[part 1 of 2: package /Nexteer/NvMProxy_swc/ComponentTypes]
AUTOSAR XML (schema 4-0-3)
package /Nexteer/NvMProxy_swc/ComponentTypes
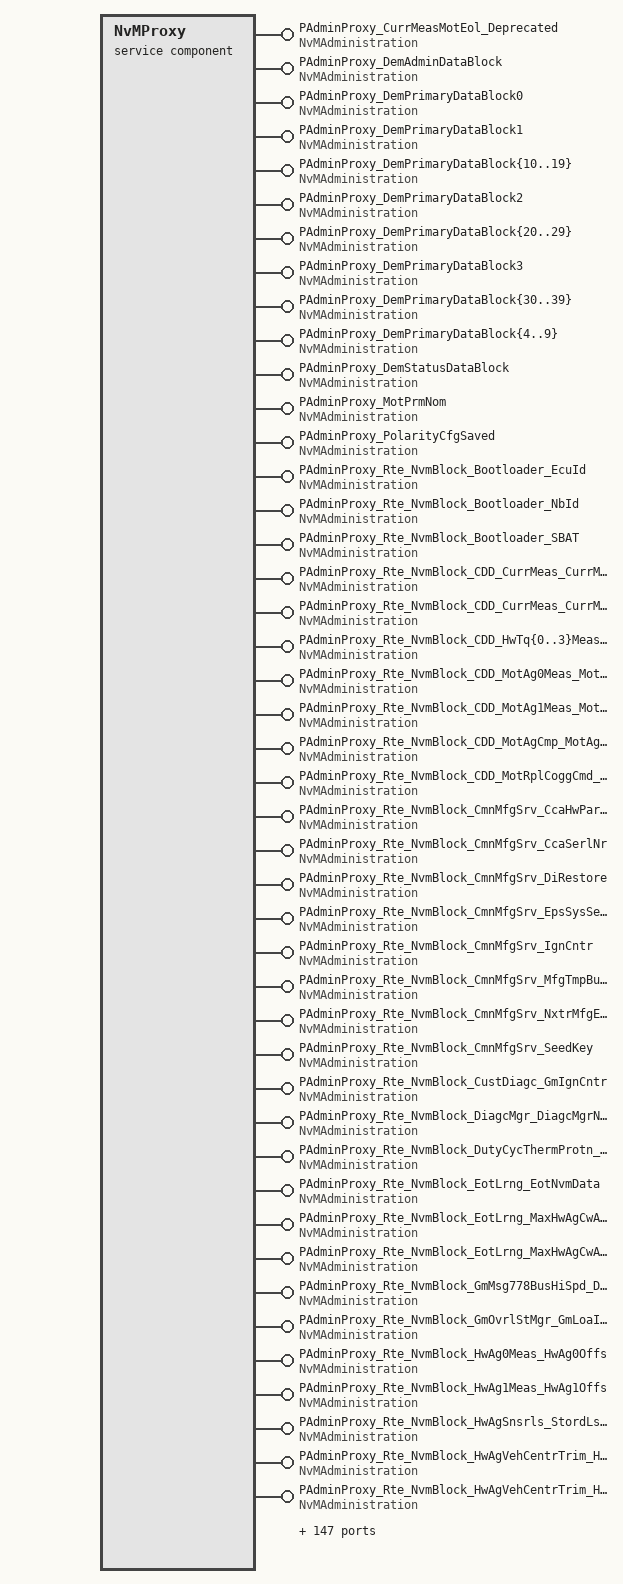
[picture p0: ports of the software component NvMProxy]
  service sw component type NvMProxy
    232 x provide port:
      PAdminProxy_CurrMeasMotEol_Deprecated: server-com-spec{operation=SetBlockProtection, queue-length=1}, provided-interface=NvMAdministration
      PAdminProxy_DemAdminDataBlock: server-com-spec{operation=SetBlockProtection, queue-length=1}, provided-interface=NvMAdministration
      PAdminProxy_DemPrimaryDataBlock0: server-com-spec{operation=SetBlockProtection, queue-length=1}, provided-interface=NvMAdministration
      PAdminProxy_DemPrimaryDataBlock1: server-com-spec{operation=SetBlockProtection, queue-length=1}, provided-interface=NvMAdministration
      PAdminProxy_DemPrimaryDataBlock{10..19}: server-com-spec{operation=SetBlockProtection, queue-length=1}, provided-interface=NvMAdministration
      PAdminProxy_DemPrimaryDataBlock2: server-com-spec{operation=SetBlockProtection, queue-length=1}, provided-interface=NvMAdministration
      PAdminProxy_DemPrimaryDataBlock{20..29}: server-com-spec{operation=SetBlockProtection, queue-length=1}, provided-interface=NvMAdministration
      PAdminProxy_DemPrimaryDataBlock3: server-com-spec{operation=SetBlockProtection, queue-length=1}, provided-interface=NvMAdministration
      PAdminProxy_DemPrimaryDataBlock{30..39}: server-com-spec{operation=SetBlockProtection, queue-length=1}, provided-interface=NvMAdministration
      PAdminProxy_DemPrimaryDataBlock{4..9}: server-com-spec{operation=SetBlockProtection, queue-length=1}, provided-interface=NvMAdministration
      PAdminProxy_DemStatusDataBlock: server-com-spec{operation=SetBlockProtection, queue-length=1}, provided-interface=NvMAdministration
      PAdminProxy_MotPrmNom: server-com-spec{operation=SetBlockProtection, queue-length=1}, provided-interface=NvMAdministration
      PAdminProxy_PolarityCfgSaved: server-com-spec{operation=SetBlockProtection, queue-length=1}, provided-interface=NvMAdministration
      PAdminProxy_Rte_NvmBlock_Bootloader_EcuId: server-com-spec{operation=SetBlockProtection, queue-length=1}, provided-interface=NvMAdministration
      PAdminProxy_Rte_NvmBlock_Bootloader_NbId: server-com-spec{operation=SetBlockProtection, queue-length=1}, provided-interface=NvMAdministration
      PAdminProxy_Rte_NvmBlock_Bootloader_SBAT: server-com-spec{operation=SetBlockProtection, queue-length=1}, provided-interface=NvMAdministration
      PAdminProxy_Rte_NvmBlock_CDD_CurrMeas_CurrMeasEolGainCalSet: server-com-spec{operation=SetBlockProtection, queue-length=1}, provided-interface=NvMAdministration
      PAdminProxy_Rte_NvmBlock_CDD_CurrMeas_CurrMeasEolOffsCalSet: server-com-spec{operation=SetBlockProtection, queue-length=1}, provided-interface=NvMAdministration
      PAdminProxy_Rte_NvmBlock_CDD_HwTq{0..3}Meas_HwTq{0..3}Offs: server-com-spec{operation=SetBlockProtection, queue-length=1}, provided-interface=NvMAdministration
      PAdminProxy_Rte_NvmBlock_CDD_MotAg0Meas_MotAg0CoeffTbl: server-com-spec{operation=SetBlockProtection, queue-length=1}, provided-interface=NvMAdministration
      PAdminProxy_Rte_NvmBlock_CDD_MotAg1Meas_MotAg1CoeffTbl: server-com-spec{operation=SetBlockProtection, queue-length=1}, provided-interface=NvMAdministration
      PAdminProxy_Rte_NvmBlock_CDD_MotAgCmp_MotAgCmpMotAgBackEmf: server-com-spec{operation=SetBlockProtection, queue-length=1}, provided-interface=NvMAdministration
      PAdminProxy_Rte_NvmBlock_CDD_MotRplCoggCmd_MotCoggCmdY: server-com-spec{operation=SetBlockProtection, queue-length=1}, provided-interface=NvMAdministration
      PAdminProxy_Rte_NvmBlock_CmnMfgSrv_CcaHwPartNr: server-com-spec{operation=SetBlockProtection, queue-length=1}, provided-interface=NvMAdministration
      PAdminProxy_Rte_NvmBlock_CmnMfgSrv_CcaSerlNr: server-com-spec{operation=SetBlockProtection, queue-length=1}, provided-interface=NvMAdministration
      PAdminProxy_Rte_NvmBlock_CmnMfgSrv_DiRestore: server-com-spec{operation=SetBlockProtection, queue-length=1}, provided-interface=NvMAdministration
      PAdminProxy_Rte_NvmBlock_CmnMfgSrv_EpsSysSerlNr: server-com-spec{operation=SetBlockProtection, queue-length=1}, provided-interface=NvMAdministration
      PAdminProxy_Rte_NvmBlock_CmnMfgSrv_IgnCntr: server-com-spec{operation=SetBlockProtection, queue-length=1}, provided-interface=NvMAdministration
      PAdminProxy_Rte_NvmBlock_CmnMfgSrv_MfgTmpBuf{0..4}: server-com-spec{operation=SetBlockProtection, queue-length=1}, provided-interface=NvMAdministration
      PAdminProxy_Rte_NvmBlock_CmnMfgSrv_NxtrMfgEnaCntr: server-com-spec{operation=SetBlockProtection, queue-length=1}, provided-interface=NvMAdministration
      PAdminProxy_Rte_NvmBlock_CmnMfgSrv_SeedKey: server-com-spec{operation=SetBlockProtection, queue-length=1}, provided-interface=NvMAdministration
      PAdminProxy_Rte_NvmBlock_CustDiagc_GmIgnCntr: server-com-spec{operation=SetBlockProtection, queue-length=1}, provided-interface=NvMAdministration
      PAdminProxy_Rte_NvmBlock_DiagcMgr_DiagcMgrNtcFltAry: server-com-spec{operation=SetBlockProtection, queue-length=1}, provided-interface=NvMAdministration
      PAdminProxy_Rte_NvmBlock_DutyCycThermProtn_FilStVal: server-com-spec{operation=SetBlockProtection, queue-length=1}, provided-interface=NvMAdministration
      PAdminProxy_Rte_NvmBlock_EotLrng_EotNvmData: server-com-spec{operation=SetBlockProtection, queue-length=1}, provided-interface=NvMAdministration
      PAdminProxy_Rte_NvmBlock_EotLrng_MaxHwAgCwAndCcw: server-com-spec{operation=SetBlockProtection, queue-length=1}, provided-interface=NvMAdministration
      PAdminProxy_Rte_NvmBlock_EotLrng_MaxHwAgCwAndCcw_Deprecated: server-com-spec{operation=SetBlockProtection, queue-length=1}, provided-interface=NvMAdministration
      PAdminProxy_Rte_NvmBlock_GmMsg778BusHiSpd_DtcTrigStsAry: server-com-spec{operation=SetBlockProtection, queue-length=1}, provided-interface=NvMAdministration
      PAdminProxy_Rte_NvmBlock_GmOvrlStMgr_GmLoaIgnCntr: server-com-spec{operation=SetBlockProtection, queue-length=1}, provided-interface=NvMAdministration
      PAdminProxy_Rte_NvmBlock_HwAg0Meas_HwAg0Offs: server-com-spec{operation=SetBlockProtection, queue-length=1}, provided-interface=NvMAdministration
      PAdminProxy_Rte_NvmBlock_HwAg1Meas_HwAg1Offs: server-com-spec{operation=SetBlockProtection, queue-length=1}, provided-interface=NvMAdministration
      PAdminProxy_Rte_NvmBlock_HwAgSnsrls_StordLstPrm: server-com-spec{operation=SetBlockProtection, queue-length=1}, provided-interface=NvMAdministration
      PAdminProxy_Rte_NvmBlock_HwAgVehCentrTrim_HwAgTrimData: server-com-spec{operation=SetBlockProtection, queue-length=1}, provided-interface=NvMAdministration
      PAdminProxy_Rte_NvmBlock_HwAgVehCentrTrim_HwAgTrimVal_Deprecated: server-com-spec{operation=SetBlockProtection, queue-length=1}, provided-interface=NvMAdministration
      PAdminProxy_Rte_NvmBlock_HwTqCorrln_HwTqChACmnModCmpLpFilSt: server-com-spec{operation=SetBlockProtection, queue-length=1}, provided-interface=NvMAdministration
      PAdminProxy_Rte_NvmBlock_HwTqCorrln_HwTqChBCmnModCmpLpFilSt: server-com-spec{operation=SetBlockProtection, queue-length=1}, provided-interface=NvMAdministration
      PAdminProxy_Rte_NvmBlock_MotAg2Meas_MotAg2EolPrm: server-com-spec{operation=SetBlockProtection, queue-length=1}, provided-interface=NvMAdministration
      PAdminProxy_Rte_NvmBlock_MotRplCoggCfg_MotRplCoggPrm: server-com-spec{operation=SetBlockProtection, queue-length=1}, provided-interface=NvMAdministration
      PAdminProxy_Rte_NvmBlock_MotTqCmdSca_MotTqScaFac: server-com-spec{operation=SetBlockProtection, queue-length=1}, provided-interface=NvMAdministration
      PAdminProxy_Rte_NvmBlock_NvMProxy_ShtdwnClsChk: server-com-spec{operation=SetBlockProtection, queue-length=1}, provided-interface=NvMAdministration
      PAdminProxy_Rte_NvmBlock_PartNr_PartNrBasMdlPartNr: server-com-spec{operation=SetBlockProtection, queue-length=1}, provided-interface=NvMAdministration
      PAdminProxy_Rte_NvmBlock_PartNr_PartNrCalProgdSts: server-com-spec{operation=SetBlockProtection, queue-length=1}, provided-interface=NvMAdministration
      PAdminProxy_Rte_NvmBlock_PartNr_PartNrCcaMfgTrakg: server-com-spec{operation=SetBlockProtection, queue-length=1}, provided-interface=NvMAdministration
      PAdminProxy_Rte_NvmBlock_PartNr_PartNrCtrlPidSeedKey: server-com-spec{operation=SetBlockProtection, queue-length=1}, provided-interface=NvMAdministration
      PAdminProxy_Rte_NvmBlock_PartNr_PartNrCustMfgEnaCntr: server-com-spec{operation=SetBlockProtection, queue-length=1}, provided-interface=NvMAdministration
      PAdminProxy_Rte_NvmBlock_PartNr_PartNrDataUniversalNrSysId: server-com-spec{operation=SetBlockProtection, queue-length=1}, provided-interface=NvMAdministration
      PAdminProxy_Rte_NvmBlock_PartNr_PartNrEndMdlPartNr: server-com-spec{operation=SetBlockProtection, queue-length=1}, provided-interface=NvMAdministration
      PAdminProxy_Rte_NvmBlock_PartNr_PartNrNxtrMfgTrakg: server-com-spec{operation=SetBlockProtection, queue-length=1}, provided-interface=NvMAdministration
      PAdminProxy_Rte_NvmBlock_PartNr_PartNrProgmDate: server-com-spec{operation=SetBlockProtection, queue-length=1}, provided-interface=NvMAdministration
      PAdminProxy_Rte_NvmBlock_PartNr_PartNrProgmSessionSeedKey: server-com-spec{operation=SetBlockProtection, queue-length=1}, provided-interface=NvMAdministration
      PAdminProxy_Rte_NvmBlock_PartNr_PartNrRepairShopCod: server-com-spec{operation=SetBlockProtection, queue-length=1}, provided-interface=NvMAdministration
      PAdminProxy_Rte_NvmBlock_PartNr_PartNrSysCodVersNr: server-com-spec{operation=SetBlockProtection, queue-length=1}, provided-interface=NvMAdministration
      PAdminProxy_Rte_NvmBlock_PartNr_PartNrSysName: server-com-spec{operation=SetBlockProtection, queue-length=1}, provided-interface=NvMAdministration
      PAdminProxy_Rte_NvmBlock_PartNr_PartNrVinData: server-com-spec{operation=SetBlockProtection, queue-length=1}, provided-interface=NvMAdministration
      PAdminProxy_Rte_NvmBlock_PullCmpActv_PullCmpLongTerm: server-com-spec{operation=SetBlockProtection, queue-length=1}, provided-interface=NvMAdministration
      PAdminProxy_Rte_NvmBlock_SnsrOffsLrng_SnsrOffsLrnd: server-com-spec{operation=SetBlockProtection, queue-length=1}, provided-interface=NvMAdministration
      PAdminProxy_Rte_NvmBlock_StHlthSigStc_SigStcHistDataAry: server-com-spec{operation=SetBlockProtection, queue-length=1}, provided-interface=NvMAdministration
      PAdminProxy_Rte_NvmBlock_SysFricLrng_FricLrngData: server-com-spec{operation=SetBlockProtection, queue-length=1}, provided-interface=NvMAdministration
      PAdminProxy_Rte_NvmBlock_SysFricLrng_FricNonLrngData: server-com-spec{operation=SetBlockProtection, queue-length=1}, provided-interface=NvMAdministration
      PAdminProxy_Rte_NvmBlock_WhlImbRejctn_ActvCmpBand{1..3}_Deprecated: server-com-spec{operation=SetBlockProtection, queue-length=1}, provided-interface=NvMAdministration
      PAdminProxy_Rte_NvmBlock_WhlImbRejctn_CmpPeakData: server-com-spec{operation=SetBlockProtection, queue-length=1}, provided-interface=NvMAdministration
      PAdminProxy_Rte_NvmBlock_WhlImbRejctn_LePeakPrev_Deprecated: server-com-spec{operation=SetBlockProtection, queue-length=1}, provided-interface=NvMAdministration
      PAdminProxy_Rte_NvmBlock_WhlImbRejctn_MaxCompPerc_Deprecated: server-com-spec{operation=SetBlockProtection, queue-length=1}, provided-interface=NvMAdministration
      PAdminProxy_Rte_NvmBlock_WhlImbRejctn_RiPeakPrev_Deprecated: server-com-spec{operation=SetBlockProtection, queue-length=1}, provided-interface=NvMAdministration
      PAdminProxy_SnpshtDataAry: server-com-spec{operation=SetBlockProtection, queue-length=1}, provided-interface=NvMAdministration
      PSProxy_CurrMeasMotEol_Deprecated: provided-interface=NvMService_AC3_SRBS
        provided-com-specs:
          operation=EraseBlock, queue-length=1
          operation=GetErrorStatus, queue-length=1
          operation=InvalidateNvBlock, queue-length=1
          operation=ReadBlock, queue-length=1
          operation=SetRamBlockStatus, queue-length=1
          operation=WriteBlock, queue-length=1
      PSProxy_DemAdminDataBlock: provided-interface=NvMService_AC3_SRBS
        provided-com-specs:
          operation=EraseBlock, queue-length=1
          operation=GetErrorStatus, queue-length=1
          operation=InvalidateNvBlock, queue-length=1
          operation=ReadBlock, queue-length=1
          operation=SetRamBlockStatus, queue-length=1
          operation=WriteBlock, queue-length=1
      PSProxy_DemPrimaryDataBlock0: provided-interface=NvMService_AC3_SRBS_Defs
        provided-com-specs:
          operation=EraseBlock, queue-length=1
          operation=GetErrorStatus, queue-length=1
          operation=InvalidateNvBlock, queue-length=1
          operation=ReadBlock, queue-length=1
          operation=RestoreBlockDefaults, queue-length=1
          operation=SetRamBlockStatus, queue-length=1
          operation=WriteBlock, queue-length=1
      PSProxy_DemPrimaryDataBlock1: provided-interface=NvMService_AC3_SRBS_Defs
        provided-com-specs:
          operation=EraseBlock, queue-length=1
          operation=GetErrorStatus, queue-length=1
          operation=InvalidateNvBlock, queue-length=1
          operation=ReadBlock, queue-length=1
          operation=RestoreBlockDefaults, queue-length=1
          operation=SetRamBlockStatus, queue-length=1
          operation=WriteBlock, queue-length=1
      PSProxy_DemPrimaryDataBlock10: provided-interface=NvMService_AC3_SRBS_Defs
        provided-com-specs:
          operation=EraseBlock, queue-length=1
          operation=GetErrorStatus, queue-length=1
          operation=InvalidateNvBlock, queue-length=1
          operation=ReadBlock, queue-length=1
          operation=RestoreBlockDefaults, queue-length=1
          operation=SetRamBlockStatus, queue-length=1
          operation=WriteBlock, queue-length=1
      PSProxy_DemPrimaryDataBlock11: provided-interface=NvMService_AC3_SRBS_Defs
        provided-com-specs:
          operation=EraseBlock, queue-length=1
          operation=GetErrorStatus, queue-length=1
          operation=InvalidateNvBlock, queue-length=1
          operation=ReadBlock, queue-length=1
          operation=RestoreBlockDefaults, queue-length=1
          operation=SetRamBlockStatus, queue-length=1
          operation=WriteBlock, queue-length=1
      PSProxy_DemPrimaryDataBlock12: provided-interface=NvMService_AC3_SRBS_Defs
        provided-com-specs:
          operation=EraseBlock, queue-length=1
          operation=GetErrorStatus, queue-length=1
          operation=InvalidateNvBlock, queue-length=1
          operation=ReadBlock, queue-length=1
          operation=RestoreBlockDefaults, queue-length=1
          operation=SetRamBlockStatus, queue-length=1
          operation=WriteBlock, queue-length=1
      PSProxy_DemPrimaryDataBlock13: provided-interface=NvMService_AC3_SRBS_Defs
        provided-com-specs:
          operation=EraseBlock, queue-length=1
          operation=GetErrorStatus, queue-length=1
          operation=InvalidateNvBlock, queue-length=1
          operation=ReadBlock, queue-length=1
          operation=RestoreBlockDefaults, queue-length=1
          operation=SetRamBlockStatus, queue-length=1
          operation=WriteBlock, queue-length=1
      PSProxy_DemPrimaryDataBlock14: provided-interface=NvMService_AC3_SRBS_Defs
        provided-com-specs:
          operation=EraseBlock, queue-length=1
          operation=GetErrorStatus, queue-length=1
          operation=InvalidateNvBlock, queue-length=1
          operation=ReadBlock, queue-length=1
          operation=RestoreBlockDefaults, queue-length=1
          operation=SetRamBlockStatus, queue-length=1
          operation=WriteBlock, queue-length=1
      PSProxy_DemPrimaryDataBlock15: provided-interface=NvMService_AC3_SRBS_Defs
        provided-com-specs:
          operation=EraseBlock, queue-length=1
          operation=GetErrorStatus, queue-length=1
          operation=InvalidateNvBlock, queue-length=1
          operation=ReadBlock, queue-length=1
          operation=RestoreBlockDefaults, queue-length=1
          operation=SetRamBlockStatus, queue-length=1
          operation=WriteBlock, queue-length=1
      PSProxy_DemPrimaryDataBlock16: provided-interface=NvMService_AC3_SRBS_Defs
        provided-com-specs:
          operation=EraseBlock, queue-length=1
          operation=GetErrorStatus, queue-length=1
          operation=InvalidateNvBlock, queue-length=1
          operation=ReadBlock, queue-length=1
          operation=RestoreBlockDefaults, queue-length=1
          operation=SetRamBlockStatus, queue-length=1
          operation=WriteBlock, queue-length=1
      PSProxy_DemPrimaryDataBlock17: provided-interface=NvMService_AC3_SRBS_Defs
        provided-com-specs:
          operation=EraseBlock, queue-length=1
          operation=GetErrorStatus, queue-length=1
          operation=InvalidateNvBlock, queue-length=1
          operation=ReadBlock, queue-length=1
          operation=RestoreBlockDefaults, queue-length=1
          operation=SetRamBlockStatus, queue-length=1
          operation=WriteBlock, queue-length=1
      PSProxy_DemPrimaryDataBlock18: provided-interface=NvMService_AC3_SRBS_Defs
        provided-com-specs:
          operation=EraseBlock, queue-length=1
          operation=GetErrorStatus, queue-length=1
          operation=InvalidateNvBlock, queue-length=1
          operation=ReadBlock, queue-length=1
          operation=RestoreBlockDefaults, queue-length=1
          operation=SetRamBlockStatus, queue-length=1
          operation=WriteBlock, queue-length=1
      PSProxy_DemPrimaryDataBlock19: provided-interface=NvMService_AC3_SRBS_Defs
        provided-com-specs:
          operation=EraseBlock, queue-length=1
          operation=GetErrorStatus, queue-length=1
          operation=InvalidateNvBlock, queue-length=1
          operation=ReadBlock, queue-length=1
          operation=RestoreBlockDefaults, queue-length=1
          operation=SetRamBlockStatus, queue-length=1
          operation=WriteBlock, queue-length=1
      PSProxy_DemPrimaryDataBlock2: provided-interface=NvMService_AC3_SRBS_Defs
        provided-com-specs:
          operation=EraseBlock, queue-length=1
          operation=GetErrorStatus, queue-length=1
          operation=InvalidateNvBlock, queue-length=1
          operation=ReadBlock, queue-length=1
          operation=RestoreBlockDefaults, queue-length=1
          operation=SetRamBlockStatus, queue-length=1
          operation=WriteBlock, queue-length=1
      PSProxy_DemPrimaryDataBlock20: provided-interface=NvMService_AC3_SRBS_Defs
        provided-com-specs:
          operation=EraseBlock, queue-length=1
          operation=GetErrorStatus, queue-length=1
          operation=InvalidateNvBlock, queue-length=1
          operation=ReadBlock, queue-length=1
          operation=RestoreBlockDefaults, queue-length=1
          operation=SetRamBlockStatus, queue-length=1
          operation=WriteBlock, queue-length=1
      PSProxy_DemPrimaryDataBlock21: provided-interface=NvMService_AC3_SRBS_Defs
        provided-com-specs:
          operation=EraseBlock, queue-length=1
          operation=GetErrorStatus, queue-length=1
          operation=InvalidateNvBlock, queue-length=1
          operation=ReadBlock, queue-length=1
          operation=RestoreBlockDefaults, queue-length=1
          operation=SetRamBlockStatus, queue-length=1
          operation=WriteBlock, queue-length=1
      PSProxy_DemPrimaryDataBlock22: provided-interface=NvMService_AC3_SRBS_Defs
        provided-com-specs:
          operation=EraseBlock, queue-length=1
          operation=GetErrorStatus, queue-length=1
          operation=InvalidateNvBlock, queue-length=1
          operation=ReadBlock, queue-length=1
          operation=RestoreBlockDefaults, queue-length=1
          operation=SetRamBlockStatus, queue-length=1
          operation=WriteBlock, queue-length=1
      PSProxy_DemPrimaryDataBlock23: provided-interface=NvMService_AC3_SRBS_Defs
        provided-com-specs:
          operation=EraseBlock, queue-length=1
          operation=GetErrorStatus, queue-length=1
          operation=InvalidateNvBlock, queue-length=1
          operation=ReadBlock, queue-length=1
          operation=RestoreBlockDefaults, queue-length=1
          operation=SetRamBlockStatus, queue-length=1
          operation=WriteBlock, queue-length=1
      PSProxy_DemPrimaryDataBlock24: provided-interface=NvMService_AC3_SRBS_Defs
        provided-com-specs:
          operation=EraseBlock, queue-length=1
          operation=GetErrorStatus, queue-length=1
          operation=InvalidateNvBlock, queue-length=1
          operation=ReadBlock, queue-length=1
          operation=RestoreBlockDefaults, queue-length=1
          operation=SetRamBlockStatus, queue-length=1
          operation=WriteBlock, queue-length=1
      PSProxy_DemPrimaryDataBlock25: provided-interface=NvMService_AC3_SRBS_Defs
        provided-com-specs:
          operation=EraseBlock, queue-length=1
          operation=GetErrorStatus, queue-length=1
          operation=InvalidateNvBlock, queue-length=1
          operation=ReadBlock, queue-length=1
          operation=RestoreBlockDefaults, queue-length=1
          operation=SetRamBlockStatus, queue-length=1
          operation=WriteBlock, queue-length=1
      PSProxy_DemPrimaryDataBlock26: provided-interface=NvMService_AC3_SRBS_Defs
        provided-com-specs:
          operation=EraseBlock, queue-length=1
          operation=GetErrorStatus, queue-length=1
          operation=InvalidateNvBlock, queue-length=1
          operation=ReadBlock, queue-length=1
          operation=RestoreBlockDefaults, queue-length=1
          operation=SetRamBlockStatus, queue-length=1
          operation=WriteBlock, queue-length=1
      PSProxy_DemPrimaryDataBlock27: provided-interface=NvMService_AC3_SRBS_Defs
        provided-com-specs:
          operation=EraseBlock, queue-length=1
          operation=GetErrorStatus, queue-length=1
          operation=InvalidateNvBlock, queue-length=1
          operation=ReadBlock, queue-length=1
          operation=RestoreBlockDefaults, queue-length=1
          operation=SetRamBlockStatus, queue-length=1
          operation=WriteBlock, queue-length=1
      PSProxy_DemPrimaryDataBlock28: provided-interface=NvMService_AC3_SRBS_Defs
        provided-com-specs:
          operation=EraseBlock, queue-length=1
          operation=GetErrorStatus, queue-length=1
          operation=InvalidateNvBlock, queue-length=1
          operation=ReadBlock, queue-length=1
          operation=RestoreBlockDefaults, queue-length=1
          operation=SetRamBlockStatus, queue-length=1
          operation=WriteBlock, queue-length=1
      PSProxy_DemPrimaryDataBlock29: provided-interface=NvMService_AC3_SRBS_Defs
        provided-com-specs:
          operation=EraseBlock, queue-length=1
          operation=GetErrorStatus, queue-length=1
          operation=InvalidateNvBlock, queue-length=1
          operation=ReadBlock, queue-length=1
          operation=RestoreBlockDefaults, queue-length=1
          operation=SetRamBlockStatus, queue-length=1
          operation=WriteBlock, queue-length=1
      PSProxy_DemPrimaryDataBlock3: provided-interface=NvMService_AC3_SRBS_Defs
        provided-com-specs:
          operation=EraseBlock, queue-length=1
          operation=GetErrorStatus, queue-length=1
          operation=InvalidateNvBlock, queue-length=1
          operation=ReadBlock, queue-length=1
          operation=RestoreBlockDefaults, queue-length=1
          operation=SetRamBlockStatus, queue-length=1
          operation=WriteBlock, queue-length=1
      PSProxy_DemPrimaryDataBlock30: provided-interface=NvMService_AC3_SRBS_Defs
        provided-com-specs:
          operation=EraseBlock, queue-length=1
          operation=GetErrorStatus, queue-length=1
          operation=InvalidateNvBlock, queue-length=1
          operation=ReadBlock, queue-length=1
          operation=RestoreBlockDefaults, queue-length=1
          operation=SetRamBlockStatus, queue-length=1
          operation=WriteBlock, queue-length=1
      PSProxy_DemPrimaryDataBlock31: provided-interface=NvMService_AC3_SRBS_Defs
        provided-com-specs:
          operation=EraseBlock, queue-length=1
          operation=GetErrorStatus, queue-length=1
          operation=InvalidateNvBlock, queue-length=1
          operation=ReadBlock, queue-length=1
          operation=RestoreBlockDefaults, queue-length=1
          operation=SetRamBlockStatus, queue-length=1
          operation=WriteBlock, queue-length=1
      PSProxy_DemPrimaryDataBlock32: provided-interface=NvMService_AC3_SRBS_Defs
        provided-com-specs:
          operation=EraseBlock, queue-length=1
          operation=GetErrorStatus, queue-length=1
          operation=InvalidateNvBlock, queue-length=1
          operation=ReadBlock, queue-length=1
          operation=RestoreBlockDefaults, queue-length=1
          operation=SetRamBlockStatus, queue-length=1
          operation=WriteBlock, queue-length=1
      PSProxy_DemPrimaryDataBlock33: provided-interface=NvMService_AC3_SRBS_Defs
        provided-com-specs:
          operation=EraseBlock, queue-length=1
          operation=GetErrorStatus, queue-length=1
          operation=InvalidateNvBlock, queue-length=1
          operation=ReadBlock, queue-length=1
          operation=RestoreBlockDefaults, queue-length=1
          operation=SetRamBlockStatus, queue-length=1
          operation=WriteBlock, queue-length=1
      PSProxy_DemPrimaryDataBlock34: provided-interface=NvMService_AC3_SRBS_Defs
        provided-com-specs:
          operation=EraseBlock, queue-length=1
          operation=GetErrorStatus, queue-length=1
          operation=InvalidateNvBlock, queue-length=1
          operation=ReadBlock, queue-length=1
          operation=RestoreBlockDefaults, queue-length=1
          operation=SetRamBlockStatus, queue-length=1
          operation=WriteBlock, queue-length=1
      PSProxy_DemPrimaryDataBlock35: provided-interface=NvMService_AC3_SRBS_Defs
        provided-com-specs:
          operation=EraseBlock, queue-length=1
          operation=GetErrorStatus, queue-length=1
          operation=InvalidateNvBlock, queue-length=1
          operation=ReadBlock, queue-length=1
          operation=RestoreBlockDefaults, queue-length=1
          operation=SetRamBlockStatus, queue-length=1
          operation=WriteBlock, queue-length=1
      PSProxy_DemPrimaryDataBlock36: provided-interface=NvMService_AC3_SRBS_Defs
        provided-com-specs:
          operation=EraseBlock, queue-length=1
          operation=GetErrorStatus, queue-length=1
          operation=InvalidateNvBlock, queue-length=1
          operation=ReadBlock, queue-length=1
          operation=RestoreBlockDefaults, queue-length=1
          operation=SetRamBlockStatus, queue-length=1
          operation=WriteBlock, queue-length=1
      PSProxy_DemPrimaryDataBlock37: provided-interface=NvMService_AC3_SRBS_Defs
        provided-com-specs:
          operation=EraseBlock, queue-length=1
          operation=GetErrorStatus, queue-length=1
          operation=InvalidateNvBlock, queue-length=1
          operation=ReadBlock, queue-length=1
          operation=RestoreBlockDefaults, queue-length=1
          operation=SetRamBlockStatus, queue-length=1
          operation=WriteBlock, queue-length=1
      PSProxy_DemPrimaryDataBlock38: provided-interface=NvMService_AC3_SRBS_Defs
        provided-com-specs:
          operation=EraseBlock, queue-length=1
          operation=GetErrorStatus, queue-length=1
          operation=InvalidateNvBlock, queue-length=1
          operation=ReadBlock, queue-length=1
          operation=RestoreBlockDefaults, queue-length=1
          operation=SetRamBlockStatus, queue-length=1
          operation=WriteBlock, queue-length=1
      PSProxy_DemPrimaryDataBlock39: provided-interface=NvMService_AC3_SRBS_Defs
        provided-com-specs:
          operation=EraseBlock, queue-length=1
          operation=GetErrorStatus, queue-length=1
          operation=InvalidateNvBlock, queue-length=1
          operation=ReadBlock, queue-length=1
          operation=RestoreBlockDefaults, queue-length=1
          operation=SetRamBlockStatus, queue-length=1
          operation=WriteBlock, queue-length=1
      PSProxy_DemPrimaryDataBlock4: provided-interface=NvMService_AC3_SRBS_Defs
        provided-com-specs:
          operation=EraseBlock, queue-length=1
          operation=GetErrorStatus, queue-length=1
          operation=InvalidateNvBlock, queue-length=1
          operation=ReadBlock, queue-length=1
          operation=RestoreBlockDefaults, queue-length=1
          operation=SetRamBlockStatus, queue-length=1
          operation=WriteBlock, queue-length=1
      PSProxy_DemPrimaryDataBlock5: provided-interface=NvMService_AC3_SRBS_Defs
        provided-com-specs:
          operation=EraseBlock, queue-length=1
          operation=GetErrorStatus, queue-length=1
          operation=InvalidateNvBlock, queue-length=1
          operation=ReadBlock, queue-length=1
          operation=RestoreBlockDefaults, queue-length=1
          operation=SetRamBlockStatus, queue-length=1
          operation=WriteBlock, queue-length=1
      PSProxy_DemPrimaryDataBlock6: provided-interface=NvMService_AC3_SRBS_Defs
        provided-com-specs:
          operation=EraseBlock, queue-length=1
          operation=GetErrorStatus, queue-length=1
          operation=InvalidateNvBlock, queue-length=1
          operation=ReadBlock, queue-length=1
          operation=RestoreBlockDefaults, queue-length=1
          operation=SetRamBlockStatus, queue-length=1
          operation=WriteBlock, queue-length=1
      PSProxy_DemPrimaryDataBlock7: provided-interface=NvMService_AC3_SRBS_Defs
        provided-com-specs:
          operation=EraseBlock, queue-length=1
          operation=GetErrorStatus, queue-length=1
          operation=InvalidateNvBlock, queue-length=1
          operation=ReadBlock, queue-length=1
          operation=RestoreBlockDefaults, queue-length=1
          operation=SetRamBlockStatus, queue-length=1
          operation=WriteBlock, queue-length=1
      PSProxy_DemPrimaryDataBlock8: provided-interface=NvMService_AC3_SRBS_Defs
        provided-com-specs:
          operation=EraseBlock, queue-length=1
          operation=GetErrorStatus, queue-length=1
          operation=InvalidateNvBlock, queue-length=1
          operation=ReadBlock, queue-length=1
          operation=RestoreBlockDefaults, queue-length=1
          operation=SetRamBlockStatus, queue-length=1
          operation=WriteBlock, queue-length=1
      PSProxy_DemPrimaryDataBlock9: provided-interface=NvMService_AC3_SRBS_Defs
        provided-com-specs:
          operation=EraseBlock, queue-length=1
          operation=GetErrorStatus, queue-length=1
          operation=InvalidateNvBlock, queue-length=1
          operation=ReadBlock, queue-length=1
          operation=RestoreBlockDefaults, queue-length=1
          operation=SetRamBlockStatus, queue-length=1
          operation=WriteBlock, queue-length=1
      PSProxy_DemStatusDataBlock: provided-interface=NvMService_AC3_SRBS
        provided-com-specs:
          operation=EraseBlock, queue-length=1
          operation=GetErrorStatus, queue-length=1
          operation=InvalidateNvBlock, queue-length=1
          operation=ReadBlock, queue-length=1
          operation=SetRamBlockStatus, queue-length=1
          operation=WriteBlock, queue-length=1
      PSProxy_MotPrmNom: provided-interface=NvMService_AC3_SRBS
        provided-com-specs:
          operation=EraseBlock, queue-length=1
          operation=GetErrorStatus, queue-length=1
          operation=InvalidateNvBlock, queue-length=1
          operation=ReadBlock, queue-length=1
          operation=SetRamBlockStatus, queue-length=1
          operation=WriteBlock, queue-length=1
      PSProxy_PolarityCfgSaved: provided-interface=NvMService_AC3_SRBS
        provided-com-specs:
          operation=EraseBlock, queue-length=1
          operation=GetErrorStatus, queue-length=1
          operation=InvalidateNvBlock, queue-length=1
          operation=ReadBlock, queue-length=1
          operation=SetRamBlockStatus, queue-length=1
          operation=WriteBlock, queue-length=1
      PSProxy_Rte_NvmBlock_Bootloader_EcuId: provided-interface=NvMService_AC3_SRBS
        provided-com-specs:
          operation=EraseBlock, queue-length=1
          operation=GetErrorStatus, queue-length=1
          operation=InvalidateNvBlock, queue-length=1
          operation=ReadBlock, queue-length=1
          operation=SetRamBlockStatus, queue-length=1
          operation=WriteBlock, queue-length=1
      PSProxy_Rte_NvmBlock_Bootloader_NbId: provided-interface=NvMService_AC3_SRBS
        provided-com-specs:
          operation=EraseBlock, queue-length=1
          operation=GetErrorStatus, queue-length=1
          operation=InvalidateNvBlock, queue-length=1
          operation=ReadBlock, queue-length=1
          operation=SetRamBlockStatus, queue-length=1
          operation=WriteBlock, queue-length=1
      PSProxy_Rte_NvmBlock_Bootloader_SBAT: provided-interface=NvMService_AC3_SRBS
        provided-com-specs:
          operation=EraseBlock, queue-length=1
          operation=GetErrorStatus, queue-length=1
          operation=InvalidateNvBlock, queue-length=1
          operation=ReadBlock, queue-length=1
          operation=SetRamBlockStatus, queue-length=1
          operation=WriteBlock, queue-length=1
      PSProxy_Rte_NvmBlock_CDD_CurrMeas_CurrMeasEolGainCalSet: provided-interface=NvMService_AC3_SRBS_Defs
        provided-com-specs:
          operation=EraseBlock, queue-length=1
          operation=GetErrorStatus, queue-length=1
          operation=InvalidateNvBlock, queue-length=1
          operation=ReadBlock, queue-length=1
          operation=RestoreBlockDefaults, queue-length=1
          operation=SetRamBlockStatus, queue-length=1
          operation=WriteBlock, queue-length=1
      PSProxy_Rte_NvmBlock_CDD_CurrMeas_CurrMeasEolOffsCalSet: provided-interface=NvMService_AC3_SRBS_Defs
        provided-com-specs:
          operation=EraseBlock, queue-length=1
          operation=GetErrorStatus, queue-length=1
          operation=InvalidateNvBlock, queue-length=1
          operation=ReadBlock, queue-length=1
          operation=RestoreBlockDefaults, queue-length=1
          operation=SetRamBlockStatus, queue-length=1
          operation=WriteBlock, queue-length=1
      PSProxy_Rte_NvmBlock_CDD_HwTq0Meas_HwTq0Offs: provided-interface=NvMService_AC3_SRBS_Defs
        provided-com-specs:
          operation=EraseBlock, queue-length=1
          operation=GetErrorStatus, queue-length=1
          operation=InvalidateNvBlock, queue-length=1
          operation=ReadBlock, queue-length=1
          operation=RestoreBlockDefaults, queue-length=1
          operation=SetRamBlockStatus, queue-length=1
          operation=WriteBlock, queue-length=1
      PSProxy_Rte_NvmBlock_CDD_HwTq1Meas_HwTq1Offs: provided-interface=NvMService_AC3_SRBS_Defs
        provided-com-specs:
          operation=EraseBlock, queue-length=1
          operation=GetErrorStatus, queue-length=1
          operation=InvalidateNvBlock, queue-length=1
          operation=ReadBlock, queue-length=1
          operation=RestoreBlockDefaults, queue-length=1
          operation=SetRamBlockStatus, queue-length=1
          operation=WriteBlock, queue-length=1
      PSProxy_Rte_NvmBlock_CDD_HwTq2Meas_HwTq2Offs: provided-interface=NvMService_AC3_SRBS_Defs
        provided-com-specs:
          operation=EraseBlock, queue-length=1
          operation=GetErrorStatus, queue-length=1
          operation=InvalidateNvBlock, queue-length=1
          operation=ReadBlock, queue-length=1
          operation=RestoreBlockDefaults, queue-length=1
          operation=SetRamBlockStatus, queue-length=1
          operation=WriteBlock, queue-length=1
      PSProxy_Rte_NvmBlock_CDD_HwTq3Meas_HwTq3Offs: provided-interface=NvMService_AC3_SRBS_Defs
        provided-com-specs:
          operation=EraseBlock, queue-length=1
          operation=GetErrorStatus, queue-length=1
          operation=InvalidateNvBlock, queue-length=1
          operation=ReadBlock, queue-length=1
          operation=RestoreBlockDefaults, queue-length=1
          operation=SetRamBlockStatus, queue-length=1
          operation=WriteBlock, queue-length=1
      PSProxy_Rte_NvmBlock_CDD_MotAg0Meas_MotAg0CoeffTbl: provided-interface=NvMService_AC3_SRBS_Defs
        provided-com-specs:
          operation=EraseBlock, queue-length=1
          operation=GetErrorStatus, queue-length=1
          operation=InvalidateNvBlock, queue-length=1
          operation=ReadBlock, queue-length=1
          operation=RestoreBlockDefaults, queue-length=1
          operation=SetRamBlockStatus, queue-length=1
          operation=WriteBlock, queue-length=1
      PSProxy_Rte_NvmBlock_CDD_MotAg1Meas_MotAg1CoeffTbl: provided-interface=NvMService_AC3_SRBS_Defs
        provided-com-specs:
          operation=EraseBlock, queue-length=1
          operation=GetErrorStatus, queue-length=1
          operation=InvalidateNvBlock, queue-length=1
          operation=ReadBlock, queue-length=1
          operation=RestoreBlockDefaults, queue-length=1
          operation=SetRamBlockStatus, queue-length=1
          operation=WriteBlock, queue-length=1
      PSProxy_Rte_NvmBlock_CDD_MotAgCmp_MotAgCmpMotAgBackEmf: provided-interface=NvMService_AC3_SRBS_Defs
        provided-com-specs:
          operation=EraseBlock, queue-length=1
          operation=GetErrorStatus, queue-length=1
          operation=InvalidateNvBlock, queue-length=1
          operation=ReadBlock, queue-length=1
          operation=RestoreBlockDefaults, queue-length=1
          operation=SetRamBlockStatus, queue-length=1
          operation=WriteBlock, queue-length=1
      PSProxy_Rte_NvmBlock_CDD_MotRplCoggCmd_MotCoggCmdY: provided-interface=NvMService_AC3_SRBS
        provided-com-specs:
          operation=EraseBlock, queue-length=1
          operation=GetErrorStatus, queue-length=1
          operation=InvalidateNvBlock, queue-length=1
          operation=ReadBlock, queue-length=1
          operation=SetRamBlockStatus, queue-length=1
          operation=WriteBlock, queue-length=1
      PSProxy_Rte_NvmBlock_CmnMfgSrv_CcaHwPartNr: provided-interface=NvMService_AC3_SRBS
        provided-com-specs:
          operation=EraseBlock, queue-length=1
          operation=GetErrorStatus, queue-length=1
          operation=InvalidateNvBlock, queue-length=1
          operation=ReadBlock, queue-length=1
          operation=SetRamBlockStatus, queue-length=1
          operation=WriteBlock, queue-length=1
      PSProxy_Rte_NvmBlock_CmnMfgSrv_CcaSerlNr: provided-interface=NvMService_AC3_SRBS
        provided-com-specs:
          operation=EraseBlock, queue-length=1
          operation=GetErrorStatus, queue-length=1
          operation=InvalidateNvBlock, queue-length=1
          operation=ReadBlock, queue-length=1
          operation=SetRamBlockStatus, queue-length=1
          operation=WriteBlock, queue-length=1
      PSProxy_Rte_NvmBlock_CmnMfgSrv_DiRestore: provided-interface=NvMService_AC3_SRBS
        provided-com-specs:
          operation=EraseBlock, queue-length=1
          operation=GetErrorStatus, queue-length=1
          operation=InvalidateNvBlock, queue-length=1
          operation=ReadBlock, queue-length=1
          operation=SetRamBlockStatus, queue-length=1
          operation=WriteBlock, queue-length=1
      PSProxy_Rte_NvmBlock_CmnMfgSrv_EpsSysSerlNr: provided-interface=NvMService_AC3_SRBS
        provided-com-specs:
          operation=EraseBlock, queue-length=1
          operation=GetErrorStatus, queue-length=1
          operation=InvalidateNvBlock, queue-length=1
          operation=ReadBlock, queue-length=1
          operation=SetRamBlockStatus, queue-length=1
          operation=WriteBlock, queue-length=1
      PSProxy_Rte_NvmBlock_CmnMfgSrv_IgnCntr: provided-interface=NvMService_AC3_SRBS_Defs
        provided-com-specs:
          operation=EraseBlock, queue-length=1
          operation=GetErrorStatus, queue-length=1
          operation=InvalidateNvBlock, queue-length=1
          operation=ReadBlock, queue-length=1
          operation=RestoreBlockDefaults, queue-length=1
          operation=SetRamBlockStatus, queue-length=1
          operation=WriteBlock, queue-length=1
      PSProxy_Rte_NvmBlock_CmnMfgSrv_MfgTmpBuf0: provided-interface=NvMService_AC3_SRBS
        provided-com-specs:
          operation=EraseBlock, queue-length=1
          operation=GetErrorStatus, queue-length=1
          operation=InvalidateNvBlock, queue-length=1
          operation=ReadBlock, queue-length=1
          operation=SetRamBlockStatus, queue-length=1
          operation=WriteBlock, queue-length=1
      PSProxy_Rte_NvmBlock_CmnMfgSrv_MfgTmpBuf1: provided-interface=NvMService_AC3_SRBS
        provided-com-specs:
          operation=EraseBlock, queue-length=1
          operation=GetErrorStatus, queue-length=1
          operation=InvalidateNvBlock, queue-length=1
          operation=ReadBlock, queue-length=1
          operation=SetRamBlockStatus, queue-length=1
          operation=WriteBlock, queue-length=1
      PSProxy_Rte_NvmBlock_CmnMfgSrv_MfgTmpBuf2: provided-interface=NvMService_AC3_SRBS
        provided-com-specs:
          operation=EraseBlock, queue-length=1
          operation=GetErrorStatus, queue-length=1
          operation=InvalidateNvBlock, queue-length=1
          operation=ReadBlock, queue-length=1
          operation=SetRamBlockStatus, queue-length=1
          operation=WriteBlock, queue-length=1
      PSProxy_Rte_NvmBlock_CmnMfgSrv_MfgTmpBuf3: provided-interface=NvMService_AC3_SRBS
        provided-com-specs:
          operation=EraseBlock, queue-length=1
          operation=GetErrorStatus, queue-length=1
          operation=InvalidateNvBlock, queue-length=1
          operation=ReadBlock, queue-length=1
          operation=SetRamBlockStatus, queue-length=1
          operation=WriteBlock, queue-length=1
      PSProxy_Rte_NvmBlock_CmnMfgSrv_MfgTmpBuf4: provided-interface=NvMService_AC3_SRBS
        provided-com-specs:
          operation=EraseBlock, queue-length=1
          operation=GetErrorStatus, queue-length=1
          operation=InvalidateNvBlock, queue-length=1
          operation=ReadBlock, queue-length=1
          operation=SetRamBlockStatus, queue-length=1
          operation=WriteBlock, queue-length=1
      PSProxy_Rte_NvmBlock_CmnMfgSrv_NxtrMfgEnaCntr: provided-interface=NvMService_AC3_SRBS_Defs
        provided-com-specs:
          operation=EraseBlock, queue-length=1
          operation=GetErrorStatus, queue-length=1
          operation=InvalidateNvBlock, queue-length=1
          operation=ReadBlock, queue-length=1
          operation=RestoreBlockDefaults, queue-length=1
          operation=SetRamBlockStatus, queue-length=1
          operation=WriteBlock, queue-length=1
      PSProxy_Rte_NvmBlock_CmnMfgSrv_SeedKey: provided-interface=NvMService_AC3_SRBS_Defs
        provided-com-specs:
          operation=EraseBlock, queue-length=1
          operation=GetErrorStatus, queue-length=1
          operation=InvalidateNvBlock, queue-length=1
          operation=ReadBlock, queue-length=1
          operation=RestoreBlockDefaults, queue-length=1
          operation=SetRamBlockStatus, queue-length=1
          operation=WriteBlock, queue-length=1
      PSProxy_Rte_NvmBlock_CustDiagc_GmIgnCntr: provided-interface=NvMService_AC3_SRBS
        provided-com-specs:
          operation=EraseBlock, queue-length=1
          operation=GetErrorStatus, queue-length=1
          operation=InvalidateNvBlock, queue-length=1
          operation=ReadBlock, queue-length=1
          operation=SetRamBlockStatus, queue-length=1
          operation=WriteBlock, queue-length=1
      PSProxy_Rte_NvmBlock_DiagcMgr_DiagcMgrNtcFltAry: provided-interface=NvMService_AC3_SRBS
        provided-com-specs:
          operation=EraseBlock, queue-length=1
          operation=GetErrorStatus, queue-length=1
          operation=InvalidateNvBlock, queue-length=1
          operation=ReadBlock, queue-length=1
          operation=SetRamBlockStatus, queue-length=1
          operation=WriteBlock, queue-length=1
      PSProxy_Rte_NvmBlock_DutyCycThermProtn_FilStVal: provided-interface=NvMService_AC3_SRBS
        provided-com-specs:
          operation=EraseBlock, queue-length=1
          operation=GetErrorStatus, queue-length=1
          operation=InvalidateNvBlock, queue-length=1
          operation=ReadBlock, queue-length=1
          operation=SetRamBlockStatus, queue-length=1
          operation=WriteBlock, queue-length=1
      PSProxy_Rte_NvmBlock_EotLrng_EotNvmData: provided-interface=NvMService_AC3_SRBS_Defs
        provided-com-specs:
          operation=EraseBlock, queue-length=1
          operation=GetErrorStatus, queue-length=1
          operation=InvalidateNvBlock, queue-length=1
          operation=ReadBlock, queue-length=1
          operation=RestoreBlockDefaults, queue-length=1
          operation=SetRamBlockStatus, queue-length=1
          operation=WriteBlock, queue-length=1
      PSProxy_Rte_NvmBlock_EotLrng_MaxHwAgCwAndCcw: provided-interface=NvMService_AC3_SRBS
        provided-com-specs:
          operation=EraseBlock, queue-length=1
          operation=GetErrorStatus, queue-length=1
          operation=InvalidateNvBlock, queue-length=1
          operation=ReadBlock, queue-length=1
          operation=SetRamBlockStatus, queue-length=1
          operation=WriteBlock, queue-length=1
      PSProxy_Rte_NvmBlock_EotLrng_MaxHwAgCwAndCcw_Deprecated: provided-interface=NvMService_AC3_SRBS
        provided-com-specs:
          operation=EraseBlock, queue-length=1
          operation=GetErrorStatus, queue-length=1
          operation=InvalidateNvBlock, queue-length=1
          operation=ReadBlock, queue-length=1
          operation=SetRamBlockStatus, queue-length=1
          operation=WriteBlock, queue-length=1
      PSProxy_Rte_NvmBlock_GmMsg778BusHiSpd_DtcTrigStsAry: provided-interface=NvMService_AC3_SRBS
        provided-com-specs:
          operation=EraseBlock, queue-length=1
          operation=GetErrorStatus, queue-length=1
          operation=InvalidateNvBlock, queue-length=1
          operation=ReadBlock, queue-length=1
          operation=SetRamBlockStatus, queue-length=1
          operation=WriteBlock, queue-length=1
      PSProxy_Rte_NvmBlock_GmOvrlStMgr_GmLoaIgnCntr: provided-interface=NvMService_AC3_SRBS
        provided-com-specs:
          operation=EraseBlock, queue-length=1
          operation=GetErrorStatus, queue-length=1
          operation=InvalidateNvBlock, queue-length=1
          operation=ReadBlock, queue-length=1
          operation=SetRamBlockStatus, queue-length=1
          operation=WriteBlock, queue-length=1
      PSProxy_Rte_NvmBlock_HwAg0Meas_HwAg0Offs: provided-interface=NvMService_AC3_SRBS_Defs
        provided-com-specs:
          operation=EraseBlock, queue-length=1
          operation=GetErrorStatus, queue-length=1
          operation=InvalidateNvBlock, queue-length=1
          operation=ReadBlock, queue-length=1
          operation=RestoreBlockDefaults, queue-length=1
          operation=SetRamBlockStatus, queue-length=1
          operation=WriteBlock, queue-length=1
      PSProxy_Rte_NvmBlock_HwAg1Meas_HwAg1Offs: provided-interface=NvMService_AC3_SRBS_Defs
        provided-com-specs:
          operation=EraseBlock, queue-length=1
          operation=GetErrorStatus, queue-length=1
          operation=InvalidateNvBlock, queue-length=1
          operation=ReadBlock, queue-length=1
          operation=RestoreBlockDefaults, queue-length=1
          operation=SetRamBlockStatus, queue-length=1
          operation=WriteBlock, queue-length=1
      PSProxy_Rte_NvmBlock_HwAgSnsrls_StordLstPrm: provided-interface=NvMService_AC3_SRBS_Defs
        provided-com-specs:
          operation=EraseBlock, queue-length=1
          operation=GetErrorStatus, queue-length=1
          operation=InvalidateNvBlock, queue-length=1
          operation=ReadBlock, queue-length=1
          operation=RestoreBlockDefaults, queue-length=1
          operation=SetRamBlockStatus, queue-length=1
          operation=WriteBlock, queue-length=1
      PSProxy_Rte_NvmBlock_HwAgVehCentrTrim_HwAgTrimData: provided-interface=NvMService_AC3_SRBS_Defs
        provided-com-specs:
          operation=EraseBlock, queue-length=1
          operation=GetErrorStatus, queue-length=1
          operation=InvalidateNvBlock, queue-length=1
          operation=ReadBlock, queue-length=1
          operation=RestoreBlockDefaults, queue-length=1
          operation=SetRamBlockStatus, queue-length=1
          operation=WriteBlock, queue-length=1
      PSProxy_Rte_NvmBlock_HwAgVehCentrTrim_HwAgTrimVal_Deprecated: provided-interface=NvMService_AC3_SRBS
        provided-com-specs:
          operation=EraseBlock, queue-length=1
          operation=GetErrorStatus, queue-length=1
          operation=InvalidateNvBlock, queue-length=1
          operation=ReadBlock, queue-length=1
          operation=SetRamBlockStatus, queue-length=1
          operation=WriteBlock, queue-length=1
      PSProxy_Rte_NvmBlock_HwTqCorrln_HwTqChACmnModCmpLpFilSt: provided-interface=NvMService_AC3_SRBS_Defs
        provided-com-specs:
          operation=EraseBlock, queue-length=1
          operation=GetErrorStatus, queue-length=1
          operation=InvalidateNvBlock, queue-length=1
          operation=ReadBlock, queue-length=1
          operation=RestoreBlockDefaults, queue-length=1
          operation=SetRamBlockStatus, queue-length=1
          operation=WriteBlock, queue-length=1
      PSProxy_Rte_NvmBlock_HwTqCorrln_HwTqChBCmnModCmpLpFilSt: provided-interface=NvMService_AC3_SRBS_Defs
        provided-com-specs:
          operation=EraseBlock, queue-length=1
          operation=GetErrorStatus, queue-length=1
          operation=InvalidateNvBlock, queue-length=1
          operation=ReadBlock, queue-length=1
          operation=RestoreBlockDefaults, queue-length=1
          operation=SetRamBlockStatus, queue-length=1
          operation=WriteBlock, queue-length=1
      PSProxy_Rte_NvmBlock_MotAg2Meas_MotAg2EolPrm: provided-interface=NvMService_AC3_SRBS_Defs
        provided-com-specs:
          operation=EraseBlock, queue-length=1
          operation=GetErrorStatus, queue-length=1
          operation=InvalidateNvBlock, queue-length=1
          operation=ReadBlock, queue-length=1
          operation=RestoreBlockDefaults, queue-length=1
          operation=SetRamBlockStatus, queue-length=1
          operation=WriteBlock, queue-length=1
      PSProxy_Rte_NvmBlock_MotRplCoggCfg_MotRplCoggPrm: provided-interface=NvMService_AC3_SRBS
        provided-com-specs:
          operation=EraseBlock, queue-length=1
          operation=GetErrorStatus, queue-length=1
          operation=InvalidateNvBlock, queue-length=1
          operation=ReadBlock, queue-length=1
          operation=SetRamBlockStatus, queue-length=1
          operation=WriteBlock, queue-length=1
      PSProxy_Rte_NvmBlock_MotTqCmdSca_MotTqScaFac: provided-interface=NvMService_AC3_SRBS
        provided-com-specs:
          operation=EraseBlock, queue-length=1
          operation=GetErrorStatus, queue-length=1
          operation=InvalidateNvBlock, queue-length=1
          operation=ReadBlock, queue-length=1
          operation=SetRamBlockStatus, queue-length=1
          operation=WriteBlock, queue-length=1
      PSProxy_Rte_NvmBlock_NvMProxy_ShtdwnClsChk: provided-interface=NvMService_AC3_SRBS
        provided-com-specs:
          operation=EraseBlock, queue-length=1
          operation=GetErrorStatus, queue-length=1
          operation=InvalidateNvBlock, queue-length=1
          operation=ReadBlock, queue-length=1
          operation=SetRamBlockStatus, queue-length=1
          operation=WriteBlock, queue-length=1
      PSProxy_Rte_NvmBlock_PartNr_PartNrBasMdlPartNr: provided-interface=NvMService_AC3_SRBS_Defs
        provided-com-specs:
          operation=EraseBlock, queue-length=1
          operation=GetErrorStatus, queue-length=1
          operation=InvalidateNvBlock, queue-length=1
          operation=ReadBlock, queue-length=1
          operation=RestoreBlockDefaults, queue-length=1
          operation=SetRamBlockStatus, queue-length=1
          operation=WriteBlock, queue-length=1
      PSProxy_Rte_NvmBlock_PartNr_PartNrCalProgdSts: provided-interface=NvMService_AC3_SRBS_Defs
        provided-com-specs:
          operation=EraseBlock, queue-length=1
          operation=GetErrorStatus, queue-length=1
          operation=InvalidateNvBlock, queue-length=1
          operation=ReadBlock, queue-length=1
          operation=RestoreBlockDefaults, queue-length=1
          operation=SetRamBlockStatus, queue-length=1
          operation=WriteBlock, queue-length=1
      PSProxy_Rte_NvmBlock_PartNr_PartNrCcaMfgTrakg: provided-interface=NvMService_AC3_SRBS_Defs
        provided-com-specs:
          operation=EraseBlock, queue-length=1
          operation=GetErrorStatus, queue-length=1
          operation=InvalidateNvBlock, queue-length=1
          operation=ReadBlock, queue-length=1
          operation=RestoreBlockDefaults, queue-length=1
          operation=SetRamBlockStatus, queue-length=1
          operation=WriteBlock, queue-length=1
      PSProxy_Rte_NvmBlock_PartNr_PartNrCtrlPidSeedKey: provided-interface=NvMService_AC3_SRBS_Defs
        provided-com-specs:
          operation=EraseBlock, queue-length=1
          operation=GetErrorStatus, queue-length=1
          operation=InvalidateNvBlock, queue-length=1
          operation=ReadBlock, queue-length=1
          operation=RestoreBlockDefaults, queue-length=1
          operation=SetRamBlockStatus, queue-length=1
          operation=WriteBlock, queue-length=1
      PSProxy_Rte_NvmBlock_PartNr_PartNrCustMfgEnaCntr: provided-interface=NvMService_AC3_SRBS_Defs
        provided-com-specs:
          operation=EraseBlock, queue-length=1
          operation=GetErrorStatus, queue-length=1
          operation=InvalidateNvBlock, queue-length=1
          operation=ReadBlock, queue-length=1
          operation=RestoreBlockDefaults, queue-length=1
          operation=SetRamBlockStatus, queue-length=1
          operation=WriteBlock, queue-length=1
      PSProxy_Rte_NvmBlock_PartNr_PartNrDataUniversalNrSysId: provided-interface=NvMService_AC3_SRBS_Defs
        provided-com-specs:
          operation=EraseBlock, queue-length=1
          operation=GetErrorStatus, queue-length=1
          operation=InvalidateNvBlock, queue-length=1
          operation=ReadBlock, queue-length=1
          operation=RestoreBlockDefaults, queue-length=1
          operation=SetRamBlockStatus, queue-length=1
          operation=WriteBlock, queue-length=1
      PSProxy_Rte_NvmBlock_PartNr_PartNrEndMdlPartNr: provided-interface=NvMService_AC3_SRBS_Defs
        provided-com-specs:
          operation=EraseBlock, queue-length=1
          operation=GetErrorStatus, queue-length=1
          operation=InvalidateNvBlock, queue-length=1
          operation=ReadBlock, queue-length=1
          operation=RestoreBlockDefaults, queue-length=1
          operation=SetRamBlockStatus, queue-length=1
          operation=WriteBlock, queue-length=1
      PSProxy_Rte_NvmBlock_PartNr_PartNrNxtrMfgTrakg: provided-interface=NvMService_AC3_SRBS_Defs
        provided-com-specs:
          operation=EraseBlock, queue-length=1
          operation=GetErrorStatus, queue-length=1
          operation=InvalidateNvBlock, queue-length=1
          operation=ReadBlock, queue-length=1
          operation=RestoreBlockDefaults, queue-length=1
          operation=SetRamBlockStatus, queue-length=1
          operation=WriteBlock, queue-length=1
      PSProxy_Rte_NvmBlock_PartNr_PartNrProgmDate: provided-interface=NvMService_AC3_SRBS_Defs
        provided-com-specs:
          operation=EraseBlock, queue-length=1
          operation=GetErrorStatus, queue-length=1
          operation=InvalidateNvBlock, queue-length=1
          operation=ReadBlock, queue-length=1
          operation=RestoreBlockDefaults, queue-length=1
          operation=SetRamBlockStatus, queue-length=1
          operation=WriteBlock, queue-length=1
      PSProxy_Rte_NvmBlock_PartNr_PartNrProgmSessionSeedKey: provided-interface=NvMService_AC3_SRBS_Defs
        provided-com-specs:
          operation=EraseBlock, queue-length=1
          operation=GetErrorStatus, queue-length=1
          operation=InvalidateNvBlock, queue-length=1
          operation=ReadBlock, queue-length=1
          operation=RestoreBlockDefaults, queue-length=1
          operation=SetRamBlockStatus, queue-length=1
          operation=WriteBlock, queue-length=1
      PSProxy_Rte_NvmBlock_PartNr_PartNrRepairShopCod: provided-interface=NvMService_AC3_SRBS_Defs
        provided-com-specs:
          operation=EraseBlock, queue-length=1
          operation=GetErrorStatus, queue-length=1
          operation=InvalidateNvBlock, queue-length=1
          operation=ReadBlock, queue-length=1
          operation=RestoreBlockDefaults, queue-length=1
          operation=SetRamBlockStatus, queue-length=1
          operation=WriteBlock, queue-length=1
      PSProxy_Rte_NvmBlock_PartNr_PartNrSysCodVersNr: provided-interface=NvMService_AC3_SRBS_Defs
        provided-com-specs:
          operation=EraseBlock, queue-length=1
          operation=GetErrorStatus, queue-length=1
          operation=InvalidateNvBlock, queue-length=1
          operation=ReadBlock, queue-length=1
          operation=RestoreBlockDefaults, queue-length=1
          operation=SetRamBlockStatus, queue-length=1
          operation=WriteBlock, queue-length=1
      PSProxy_Rte_NvmBlock_PartNr_PartNrSysName: provided-interface=NvMService_AC3_SRBS_Defs
        provided-com-specs:
          operation=EraseBlock, queue-length=1
          operation=GetErrorStatus, queue-length=1
          operation=InvalidateNvBlock, queue-length=1
          operation=ReadBlock, queue-length=1
          operation=RestoreBlockDefaults, queue-length=1
          operation=SetRamBlockStatus, queue-length=1
          operation=WriteBlock, queue-length=1
      PSProxy_Rte_NvmBlock_PartNr_PartNrVinData: provided-interface=NvMService_AC3_SRBS_Defs
        provided-com-specs:
          operation=EraseBlock, queue-length=1
          operation=GetErrorStatus, queue-length=1
          operation=InvalidateNvBlock, queue-length=1
          operation=ReadBlock, queue-length=1
          operation=RestoreBlockDefaults, queue-length=1
          operation=SetRamBlockStatus, queue-length=1
          operation=WriteBlock, queue-length=1
      PSProxy_Rte_NvmBlock_PullCmpActv_PullCmpLongTerm: provided-interface=NvMService_AC3_SRBS_Defs
        provided-com-specs:
          operation=EraseBlock, queue-length=1
          operation=GetErrorStatus, queue-length=1
          operation=InvalidateNvBlock, queue-length=1
          operation=ReadBlock, queue-length=1
          operation=RestoreBlockDefaults, queue-length=1
          operation=SetRamBlockStatus, queue-length=1
          operation=WriteBlock, queue-length=1
      PSProxy_Rte_NvmBlock_SnsrOffsLrng_SnsrOffsLrnd: provided-interface=NvMService_AC3_SRBS
        provided-com-specs:
          operation=EraseBlock, queue-length=1
          operation=GetErrorStatus, queue-length=1
          operation=InvalidateNvBlock, queue-length=1
          operation=ReadBlock, queue-length=1
          operation=SetRamBlockStatus, queue-length=1
          operation=WriteBlock, queue-length=1
      PSProxy_Rte_NvmBlock_StHlthSigStc_SigStcHistDataAry: provided-interface=NvMService_AC3_SRBS
        provided-com-specs:
          operation=EraseBlock, queue-length=1
          operation=GetErrorStatus, queue-length=1
          operation=InvalidateNvBlock, queue-length=1
          operation=ReadBlock, queue-length=1
          operation=SetRamBlockStatus, queue-length=1
          operation=WriteBlock, queue-length=1
      PSProxy_Rte_NvmBlock_SysFricLrng_FricLrngData: provided-interface=NvMService_AC3_SRBS_Defs
        provided-com-specs:
          operation=EraseBlock, queue-length=1
          operation=GetErrorStatus, queue-length=1
          operation=InvalidateNvBlock, queue-length=1
          operation=ReadBlock, queue-length=1
          operation=RestoreBlockDefaults, queue-length=1
          operation=SetRamBlockStatus, queue-length=1
          operation=WriteBlock, queue-length=1
      PSProxy_Rte_NvmBlock_SysFricLrng_FricNonLrngData: provided-interface=NvMService_AC3_SRBS_Defs
        provided-com-specs:
          operation=EraseBlock, queue-length=1
          operation=GetErrorStatus, queue-length=1
          operation=InvalidateNvBlock, queue-length=1
          operation=ReadBlock, queue-length=1
          operation=RestoreBlockDefaults, queue-length=1
          operation=SetRamBlockStatus, queue-length=1
          operation=WriteBlock, queue-length=1
      PSProxy_Rte_NvmBlock_WhlImbRejctn_ActvCmpBand1_Deprecated: provided-interface=NvMService_AC3_SRBS
        provided-com-specs:
          operation=EraseBlock, queue-length=1
          operation=GetErrorStatus, queue-length=1
          operation=InvalidateNvBlock, queue-length=1
          operation=ReadBlock, queue-length=1
          operation=SetRamBlockStatus, queue-length=1
          operation=WriteBlock, queue-length=1
      PSProxy_Rte_NvmBlock_WhlImbRejctn_ActvCmpBand2_Deprecated: provided-interface=NvMService_AC3_SRBS
        provided-com-specs:
          operation=EraseBlock, queue-length=1
          operation=GetErrorStatus, queue-length=1
          operation=InvalidateNvBlock, queue-length=1
          operation=ReadBlock, queue-length=1
          operation=SetRamBlockStatus, queue-length=1
          operation=WriteBlock, queue-length=1
      PSProxy_Rte_NvmBlock_WhlImbRejctn_ActvCmpBand3_Deprecated: provided-interface=NvMService_AC3_SRBS
        provided-com-specs:
          operation=EraseBlock, queue-length=1
          operation=GetErrorStatus, queue-length=1
          operation=InvalidateNvBlock, queue-length=1
          operation=ReadBlock, queue-length=1
          operation=SetRamBlockStatus, queue-length=1
          operation=WriteBlock, queue-length=1
      PSProxy_Rte_NvmBlock_WhlImbRejctn_CmpPeakData: provided-interface=NvMService_AC3_SRBS
        provided-com-specs:
          operation=EraseBlock, queue-length=1
          operation=GetErrorStatus, queue-length=1
          operation=InvalidateNvBlock, queue-length=1
          operation=ReadBlock, queue-length=1
          operation=SetRamBlockStatus, queue-length=1
          operation=WriteBlock, queue-length=1
      PSProxy_Rte_NvmBlock_WhlImbRejctn_LePeakPrev_Deprecated: provided-interface=NvMService_AC3_SRBS
        provided-com-specs:
          operation=EraseBlock, queue-length=1
          operation=GetErrorStatus, queue-length=1
          operation=InvalidateNvBlock, queue-length=1
          operation=ReadBlock, queue-length=1
          operation=SetRamBlockStatus, queue-length=1
          operation=WriteBlock, queue-length=1
      PSProxy_Rte_NvmBlock_WhlImbRejctn_MaxCompPerc_Deprecated: provided-interface=NvMService_AC3_SRBS
        provided-com-specs:
          operation=EraseBlock, queue-length=1
          operation=GetErrorStatus, queue-length=1
          operation=InvalidateNvBlock, queue-length=1
          operation=ReadBlock, queue-length=1
          operation=SetRamBlockStatus, queue-length=1
          operation=WriteBlock, queue-length=1
      PSProxy_Rte_NvmBlock_WhlImbRejctn_RiPeakPrev_Deprecated: provided-interface=NvMService_AC3_SRBS
        provided-com-specs:
          operation=EraseBlock, queue-length=1
          operation=GetErrorStatus, queue-length=1
          operation=InvalidateNvBlock, queue-length=1
          operation=ReadBlock, queue-length=1
          operation=SetRamBlockStatus, queue-length=1
          operation=WriteBlock, queue-length=1
      PSProxy_SnpshtDataAry: provided-interface=NvMService_AC3_SRBS
        provided-com-specs:
          operation=EraseBlock, queue-length=1
          operation=GetErrorStatus, queue-length=1
          operation=InvalidateNvBlock, queue-length=1
          operation=ReadBlock, queue-length=1
          operation=SetRamBlockStatus, queue-length=1
          operation=WriteBlock, queue-length=1
